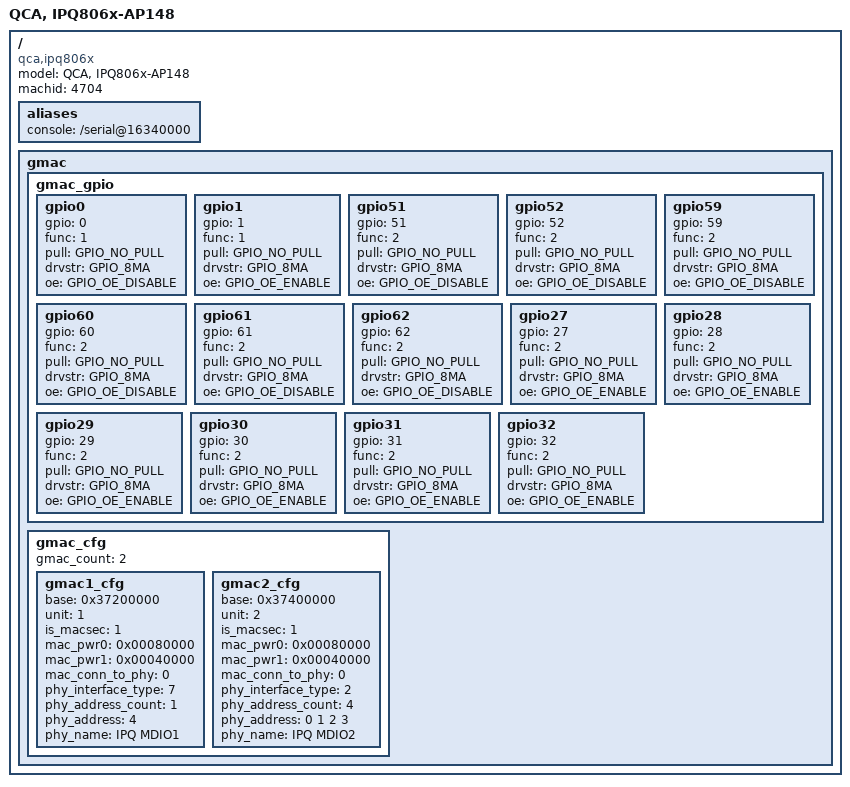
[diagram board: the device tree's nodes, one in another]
/*
 * Copyright (c) 2016, The Linux Foundation. All rights reserved.
 *
 * This program is free software; you can redistribute it and/or modify
 * it under the terms of the GNU General Public License version 2 and
 * only version 2 as published by the Free Software Foundation.
 *
 * This program is distributed in the hope that it will be useful,
 * but WITHOUT ANY WARRANTY; without even the implied warranty of
 * MERCHANTABILITY or FITNESS FOR A PARTICULAR PURPOSE.  See the
 * GNU General Public License for more details.
 */

/dts-v1/;
#include "ipq806x-soc.dtsi"
/ {
	model ="QCA, IPQ806x-AP148";
	compatible = "qca,ipq806x", "qca,ipq806x-ap148";
	machid = <4704>;
	aliases {
		console = "/serial@16340000";
	};

	gmac {
		gmac_gpio {
			gpio0 {
				gpio = <0>;
				func = <1>;
				pull = <GPIO_NO_PULL>;
				drvstr = <GPIO_8MA>;
				oe = <GPIO_OE_DISABLE>;
			};

			gpio1 {
				gpio = <1>;
				func = <1>;
				pull = <GPIO_NO_PULL>;
				drvstr = <GPIO_8MA>;
				oe = <GPIO_OE_ENABLE>;
			};

			gpio51 {
				gpio = <51>;
				func = <2>;
				pull = <GPIO_NO_PULL>;
				drvstr = <GPIO_8MA>;
				oe = <GPIO_OE_DISABLE>;
			};

			gpio52 {
				gpio = <52>;
				func = <2>;
				pull = <GPIO_NO_PULL>;
				drvstr = <GPIO_8MA>;
				oe = <GPIO_OE_DISABLE>;
			};

			gpio59 {
				gpio = <59>;
				func = <2>;
				pull = <GPIO_NO_PULL>;
				drvstr = <GPIO_8MA>;
				oe = <GPIO_OE_DISABLE>;
			};

			gpio60 {
				gpio = <60>;
				func = <2>;
				pull = <GPIO_NO_PULL>;
				drvstr = <GPIO_8MA>;
				oe = <GPIO_OE_DISABLE>;
			};

			gpio61 {
				gpio = <61>;
				func = <2>;
				pull = <GPIO_NO_PULL>;
				drvstr = <GPIO_8MA>;
				oe = <GPIO_OE_DISABLE>;
			};

			gpio62 {
				gpio = <62>;
				func = <2>;
				pull = <GPIO_NO_PULL>;
				drvstr = <GPIO_8MA>;
				oe = <GPIO_OE_DISABLE>;
			};

			gpio27 {
				gpio = <27>;
				func = <2>;
				pull = <GPIO_NO_PULL>;
				drvstr = <GPIO_8MA>;
				oe = <GPIO_OE_ENABLE>;
			};

			gpio28 {
				gpio = <28>;
				func = <2>;
				pull = <GPIO_NO_PULL>;
				drvstr = <GPIO_8MA>;
				oe = <GPIO_OE_ENABLE>;
			};

			gpio29 {
				gpio = <29>;
				func = <2>;
				pull = <GPIO_NO_PULL>;
				drvstr = <GPIO_8MA>;
				oe = <GPIO_OE_ENABLE>;
			};

			gpio30 {
				gpio = <30>;
				func = <2>;
				pull = <GPIO_NO_PULL>;
				drvstr = <GPIO_8MA>;
				oe = <GPIO_OE_ENABLE>;
			};

			gpio31 {
				gpio = <31>;
				func = <2>;
				pull = <GPIO_NO_PULL>;
				drvstr = <GPIO_8MA>;
				oe = <GPIO_OE_ENABLE>;
			};

			gpio32 {
				gpio = <32>;
				func = <2>;
				pull = <GPIO_NO_PULL>;
				drvstr = <GPIO_8MA>;
				oe = <GPIO_OE_ENABLE>;
			};
		};

		gmac_cfg {
			gmac_count = <2>;

			gmac1_cfg {
				base = <0x37200000>;
				unit = <1>;
				is_macsec = <1>;
				mac_pwr0 = <0x00080000>;
				mac_pwr1 = <0x00040000>;
				mac_conn_to_phy = <0>;
				phy_interface_type = <7>;
				phy_address_count = <1>;
				phy_address = <4>;
				phy_name = "IPQ MDIO1";
			};

			gmac2_cfg {
				base = <0x37400000>;
				unit = <2>;
				is_macsec = <1>;
				mac_pwr0 = <0x00080000>;
				mac_pwr1 = <0x00040000>;
				mac_conn_to_phy = <0>;
				phy_interface_type = <2>;
				phy_address_count = <4>;
				phy_address = <0 1 2 3>;
				phy_name = "IPQ MDIO2";
			};
		};

	};
};
